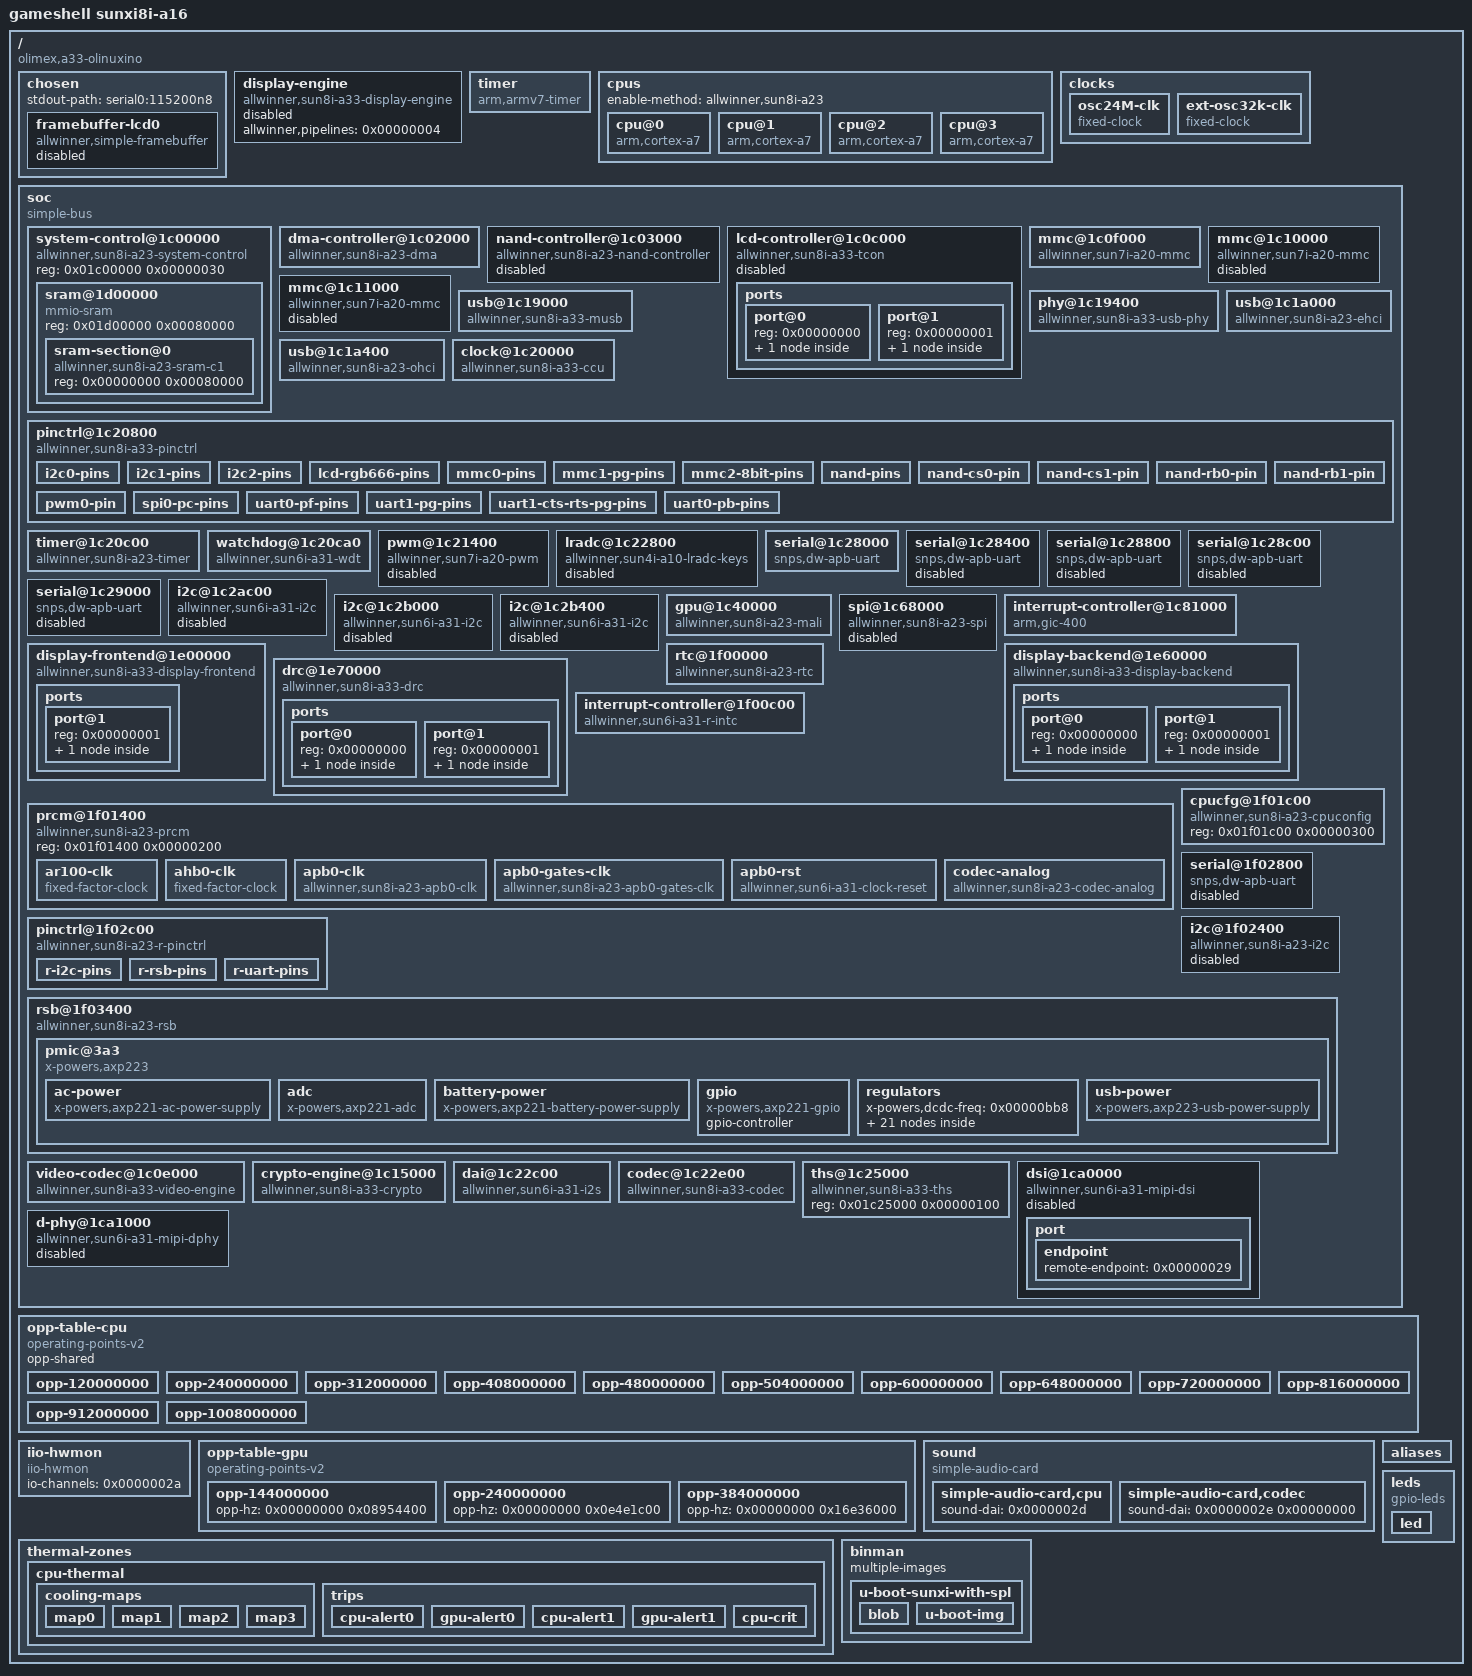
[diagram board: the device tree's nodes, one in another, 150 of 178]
/ {
        interrupt-parent = <0x00000001>;
        #address-cells = <0x00000001>;
        #size-cells = <0x00000001>;
        model = "gameshell sunxi8i-a16";
        compatible = "olimex,a33-olinuxino", "allwinner,sun8i-a33";
        chosen {
                #address-cells = <0x00000001>;
                #size-cells = <0x00000001>;
                ranges;
                stdout-path = "serial0:115200n8";
                framebuffer-lcd0 {
                        compatible = "allwinner,simple-framebuffer", "simple-framebuffer";
                        allwinner,pipeline = "de_be0-lcd0";
                        clocks = <0x00000002 0x00000026 0x00000002 0x00000028 0x00000002 0x00000057 0x00000002 0x00000055 0x00000002 0x00000054 0x00000002 0x00000062>;
                        status = "disabled";
                        vcc-lcd-supply = <0x00000003>;
                        phandle = <0x00000038>;
                };
        };
        display-engine {
                allwinner,pipelines = <0x00000004>;
                status = "disabled";
                compatible = "allwinner,sun8i-a33-display-engine";
                phandle = <0x00000039>;
        };
        timer {
                compatible = "arm,armv7-timer";
                interrupts = <0x00000001 0x0000000d 0x00000f08 0x00000001 0x0000000e 0x00000f08 0x00000001 0x0000000b 0x00000f08 0x00000001 0x0000000a 0x00000f08>;
                clock-frequency = <0x016e3600>;
                arm,cpu-registers-not-fw-configured;
        };
        cpus {
                enable-method = "allwinner,sun8i-a23";
                #address-cells = <0x00000001>;
                #size-cells = <0x00000000>;
                cpu@0 {
                        compatible = "arm,cortex-a7";
                        device_type = "cpu";
                        reg = <0x00000000>;
                        clocks = <0x00000002 0x00000012>;
                        clock-names = "cpu";
                        operating-points-v2 = <0x00000005>;
                        #cooling-cells = <0x00000002>;
                        phandle = <0x00000030>;
                };
                cpu@1 {
                        compatible = "arm,cortex-a7";
                        device_type = "cpu";
                        reg = <0x00000001>;
                        clocks = <0x00000002 0x00000012>;
                        clock-names = "cpu";
                        operating-points-v2 = <0x00000005>;
                        #cooling-cells = <0x00000002>;
                        phandle = <0x00000031>;
                };
                cpu@2 {
                        compatible = "arm,cortex-a7";
                        device_type = "cpu";
                        reg = <0x00000002>;
                        clocks = <0x00000002 0x00000012>;
                        clock-names = "cpu";
                        operating-points-v2 = <0x00000005>;
                        #cooling-cells = <0x00000002>;
                        phandle = <0x00000032>;
                };
                cpu@3 {
                        compatible = "arm,cortex-a7";
                        device_type = "cpu";
                        reg = <0x00000003>;
                        clocks = <0x00000002 0x00000012>;
                        clock-names = "cpu";
                        operating-points-v2 = <0x00000005>;
                        #cooling-cells = <0x00000002>;
                        phandle = <0x00000033>;
                };
        };
        clocks {
                #address-cells = <0x00000001>;
                #size-cells = <0x00000001>;
                ranges;
                osc24M-clk {
                        #clock-cells = <0x00000000>;
                        compatible = "fixed-clock";
                        clock-frequency = <0x016e3600>;
                        clock-accuracy = <0x0000c350>;
                        clock-output-names = "osc24M";
                        phandle = <0x00000012>;
                };
                ext-osc32k-clk {
                        #clock-cells = <0x00000000>;
                        compatible = "fixed-clock";
                        clock-frequency = <0x00008000>;
                        clock-accuracy = <0x0000c350>;
                        clock-output-names = "ext-osc32k";
                        phandle = <0x0000001e>;
                };
        };
        soc {
                compatible = "simple-bus";
                #address-cells = <0x00000001>;
                #size-cells = <0x00000001>;
                ranges;
                system-control@1c00000 {
                        compatible = "allwinner,sun8i-a23-system-control";
                        reg = <0x01c00000 0x00000030>;
                        #address-cells = <0x00000001>;
                        #size-cells = <0x00000001>;
                        ranges;
                        sram@1d00000 {
                                compatible = "mmio-sram";
                                reg = <0x01d00000 0x00080000>;
                                #address-cells = <0x00000001>;
                                #size-cells = <0x00000001>;
                                ranges = <0x00000000 0x01d00000 0x00080000>;
                                phandle = <0x0000003a>;
                                sram-section@0 {
                                        compatible = "allwinner,sun8i-a23-sram-c1", "allwinner,sun4i-a10-sram-c1";
                                        reg = <0x00000000 0x00080000>;
                                        phandle = <0x00000027>;
                                };
                        };
                };
                dma-controller@1c02000 {
                        compatible = "allwinner,sun8i-a23-dma";
                        reg = <0x01c02000 0x00001000>;
                        interrupts = <0x00000000 0x00000032 0x00000004>;
                        clocks = <0x00000002 0x00000019>;
                        resets = <0x00000002 0x00000006>;
                        #dma-cells = <0x00000001>;
                        phandle = <0x00000006>;
                };
                nand-controller@1c03000 {
                        compatible = "allwinner,sun8i-a23-nand-controller";
                        reg = <0x01c03000 0x00001000>;
                        interrupts = <0x00000000 0x00000046 0x00000004>;
                        clocks = <0x00000002 0x0000001d 0x00000002 0x0000003b>;
                        clock-names = "ahb", "mod";
                        resets = <0x00000002 0x0000000a>;
                        reset-names = "ahb";
                        dmas = <0x00000006 0x00000005>;
                        dma-names = "rxtx";
                        pinctrl-names = "default";
                        pinctrl-0 = <0x00000007 0x00000008 0x00000009>;
                        status = "disabled";
                        #address-cells = <0x00000001>;
                        #size-cells = <0x00000000>;
                        phandle = <0x0000003b>;
                };
                lcd-controller@1c0c000 {
                        reg = <0x01c0c000 0x00001000>;
                        interrupts = <0x00000000 0x00000056 0x00000004>;
                        dmas = <0x00000006 0x0000000c>;
                        clocks = <0x00000002 0x00000026 0x00000002 0x00000057 0x00000002 0x0000000d>;
                        clock-names = "ahb", "tcon-ch0", "lvds-alt";
                        clock-output-names = "tcon-data-clock";
                        #clock-cells = <0x00000000>;
                        resets = <0x00000002 0x00000013 0x00000002 0x0000001c>;
                        reset-names = "lcd", "lvds";
                        status = "disabled";
                        compatible = "allwinner,sun8i-a33-tcon";
                        phandle = <0x0000003c>;
                        ports {
                                #address-cells = <0x00000001>;
                                #size-cells = <0x00000000>;
                                port@0 {
                                        reg = <0x00000000>;
                                        phandle = <0x0000003d>;
                                        endpoint {
                                                remote-endpoint = <0x0000000a>;
                                                phandle = <0x0000001d>;
                                        };
                                };
                                port@1 {
                                        reg = <0x00000001>;
                                        #address-cells = <0x00000001>;
                                        #size-cells = <0x00000000>;
                                        phandle = <0x0000003e>;
                                        endpoint@1 {
                                                reg = <0x00000001>;
                                                remote-endpoint = <0x0000000b>;
                                                phandle = <0x00000029>;
                                        };
                                };
                        };
                };
                mmc@1c0f000 {
                        compatible = "allwinner,sun7i-a20-mmc";
                        reg = <0x01c0f000 0x00001000>;
                        clocks = <0x00000002 0x0000001a 0x00000002 0x0000003c 0x00000002 0x0000003e 0x00000002 0x0000003d>;
                        clock-names = "ahb", "mmc", "output", "sample";
                        resets = <0x00000002 0x00000007>;
                        reset-names = "ahb";
                        interrupts = <0x00000000 0x0000003c 0x00000004>;
                        pinctrl-names = "default";
                        pinctrl-0 = <0x0000000c>;
                        status = "okay";
                        #address-cells = <0x00000001>;
                        #size-cells = <0x00000000>;
                        vmmc-supply = <0x0000000d>;
                        bus-width = <0x00000004>;
                        cd-gpios = <0x0000000e 0x00000001 0x00000004 0x00000001>;
                        phandle = <0x0000003f>;
                };
                mmc@1c10000 {
                        compatible = "allwinner,sun7i-a20-mmc";
                        reg = <0x01c10000 0x00001000>;
                        clocks = <0x00000002 0x0000001b 0x00000002 0x0000003f 0x00000002 0x00000041 0x00000002 0x00000040>;
                        clock-names = "ahb", "mmc", "output", "sample";
                        resets = <0x00000002 0x00000008>;
                        reset-names = "ahb";
                        interrupts = <0x00000000 0x0000003d 0x00000004>;
                        status = "disabled";
                        #address-cells = <0x00000001>;
                        #size-cells = <0x00000000>;
                        phandle = <0x00000040>;
                };
                mmc@1c11000 {
                        compatible = "allwinner,sun7i-a20-mmc";
                        reg = <0x01c11000 0x00001000>;
                        clocks = <0x00000002 0x0000001c 0x00000002 0x00000042 0x00000002 0x00000044 0x00000002 0x00000043>;
                        clock-names = "ahb", "mmc", "output", "sample";
                        resets = <0x00000002 0x00000009>;
                        reset-names = "ahb";
                        interrupts = <0x00000000 0x0000003e 0x00000004>;
                        status = "disabled";
                        #address-cells = <0x00000001>;
                        #size-cells = <0x00000000>;
                        phandle = <0x00000041>;
                };
                usb@1c19000 {
                        reg = <0x01c19000 0x00000400>;
                        clocks = <0x00000002 0x00000022>;
                        resets = <0x00000002 0x0000000f>;
                        interrupts = <0x00000000 0x00000047 0x00000004>;
                        interrupt-names = "mc";
                        phys = <0x0000000f 0x00000000>;
                        phy-names = "usb";
                        extcon = <0x0000000f 0x00000000>;
                        dr_mode = "otg";
                        status = "okay";
                        compatible = "allwinner,sun8i-a33-musb";
                        phandle = <0x00000042>;
                };
                phy@1c19400 {
                        clocks = <0x00000002 0x0000004a 0x00000002 0x0000004b>;
                        clock-names = "usb0_phy", "usb1_phy";
                        resets = <0x00000002 0x00000000 0x00000002 0x00000001>;
                        reset-names = "usb0_reset", "usb1_reset";
                        status = "okay";
                        #phy-cells = <0x00000001>;
                        compatible = "allwinner,sun8i-a33-usb-phy";
                        reg = <0x01c19400 0x00000014 0x01c1a800 0x00000004>;
                        reg-names = "phy_ctrl", "pmu1";
                        usb0_id_det-gpios = <0x0000000e 0x00000001 0x00000003 0x00000000>;
                        usb0_vbus_power-supply = <0x00000010>;
                        usb0_vbus-supply = <0x00000011>;
                        phandle = <0x0000000f>;
                };
                usb@1c1a000 {
                        compatible = "allwinner,sun8i-a23-ehci", "generic-ehci";
                        reg = <0x01c1a000 0x00000100>;
                        interrupts = <0x00000000 0x00000048 0x00000004>;
                        clocks = <0x00000002 0x00000023>;
                        resets = <0x00000002 0x00000010>;
                        phys = <0x0000000f 0x00000001>;
                        phy-names = "usb";
                        status = "okay";
                        phandle = <0x00000043>;
                };
                usb@1c1a400 {
                        compatible = "allwinner,sun8i-a23-ohci", "generic-ohci";
                        reg = <0x01c1a400 0x00000100>;
                        interrupts = <0x00000000 0x00000049 0x00000004>;
                        clocks = <0x00000002 0x00000024 0x00000002 0x0000004e>;
                        resets = <0x00000002 0x00000011>;
                        phys = <0x0000000f 0x00000001>;
                        phy-names = "usb";
                        status = "okay";
                        phandle = <0x00000044>;
                };
                clock@1c20000 {
                        reg = <0x01c20000 0x00000400>;
                        clocks = <0x00000012 0x00000013 0x00000000>;
                        clock-names = "hosc", "losc";
                        #clock-cells = <0x00000001>;
                        #reset-cells = <0x00000001>;
                        compatible = "allwinner,sun8i-a33-ccu";
                        phandle = <0x00000002>;
                };
                pinctrl@1c20800 {
                        reg = <0x01c20800 0x00000400>;
                        clocks = <0x00000002 0x00000030 0x00000012 0x00000013 0x00000000>;
                        clock-names = "apb", "hosc", "losc";
                        gpio-controller;
                        interrupt-controller;
                        #interrupt-cells = <0x00000003>;
                        #gpio-cells = <0x00000003>;
                        compatible = "allwinner,sun8i-a33-pinctrl";
                        interrupts = <0x00000000 0x0000000f 0x00000004 0x00000000 0x00000011 0x00000004>;
                        phandle = <0x0000000e>;
                        i2c0-pins {
                                pins = "PH2", "PH3";
                                function = "i2c0";
                                phandle = <0x00000015>;
                        };
                        i2c1-pins {
                                pins = "PH4", "PH5";
                                function = "i2c1";
                                phandle = <0x00000016>;
                        };
                        i2c2-pins {
                                pins = "PE12", "PE13";
                                function = "i2c2";
                                phandle = <0x00000017>;
                        };
                        lcd-rgb666-pins {
                                pins = "PD2", "PD3", "PD4", "PD5", "PD6", "PD7", "PD10", "PD11", "PD12", "PD13", "PD14", "PD15", "PD18", "PD19", "PD20", "PD21", "PD22", "PD23", "PD24", "PD25", "PD26", "PD27";
                                function = "lcd0";
                                phandle = <0x00000045>;
                        };
                        mmc0-pins {
                                pins = "PF0", "PF1", "PF2", "PF3", "PF4", "PF5";
                                function = "mmc0";
                                drive-strength = <0x0000001e>;
                                bias-pull-up;
                                phandle = <0x0000000c>;
                        };
                        mmc1-pg-pins {
                                pins = "PG0", "PG1", "PG2", "PG3", "PG4", "PG5";
                                function = "mmc1";
                                drive-strength = <0x0000001e>;
                                bias-pull-up;
                                phandle = <0x00000046>;
                        };
                        mmc2-8bit-pins {
                                pins = "PC5", "PC6", "PC8", "PC9", "PC10", "PC11", "PC12", "PC13", "PC14", "PC15", "PC16";
                                function = "mmc2";
                                drive-strength = <0x0000001e>;
                                bias-pull-up;
                                phandle = <0x00000047>;
                        };
                        nand-pins {
                                pins = "PC0", "PC1", "PC2", "PC5", "PC8", "PC9", "PC10", "PC11", "PC12", "PC13", "PC14", "PC15";
                                function = "nand0";
                                phandle = <0x00000007>;
                        };
                        nand-cs0-pin {
                                pins = "PC4";
                                function = "nand0";
                                bias-pull-up;
                                phandle = <0x00000008>;
                        };
                        nand-cs1-pin {
                                pins = "PC3";
                                function = "nand0";
                                bias-pull-up;
                                phandle = <0x00000048>;
                        };
                        nand-rb0-pin {
                                pins = "PC6";
                                function = "nand0";
                                bias-pull-up;
                                phandle = <0x00000009>;
                        };
                        nand-rb1-pin {
                                pins = "PC7";
                                function = "nand0";
                                bias-pull-up;
                                phandle = <0x00000049>;
                        };
                        pwm0-pin {
                                pins = "PH0";
                                function = "pwm0";
                                phandle = <0x0000004a>;
                        };
                        spi0-pc-pins {
                                pins = "PC0", "PC1", "PC2", "PC3";
                                function = "spi0";
                                phandle = <0x0000004b>;
                        };
                        uart0-pf-pins {
                                pins = "PF2", "PF4";
                                function = "uart0";
                                phandle = <0x0000004c>;
                        };
                        uart1-pg-pins {
                                pins = "PG6", "PG7";
                                function = "uart1";
                                phandle = <0x0000004d>;
                        };
                        uart1-cts-rts-pg-pins {
                                pins = "PG8", "PG9";
                                function = "uart1";
                                phandle = <0x0000004e>;
                        };
                        uart0-pb-pins {
                                pins = "PB0", "PB1";
                                function = "uart0";
                                phandle = <0x00000014>;
                        };
                };
                timer@1c20c00 {
                        compatible = "allwinner,sun8i-a23-timer";
                        reg = <0x01c20c00 0x000000a0>;
                        interrupts = <0x00000000 0x00000012 0x00000004 0x00000000 0x00000013 0x00000004>;
                        clocks = <0x00000012>;
                };
                watchdog@1c20ca0 {
                        compatible = "allwinner,sun6i-a31-wdt";
                        reg = <0x01c20ca0 0x00000020>;
                        interrupts = <0x00000000 0x00000019 0x00000004>;
                        clocks = <0x00000012>;
                        phandle = <0x0000004f>;
                };
                pwm@1c21400 {
                        compatible = "allwinner,sun7i-a20-pwm";
                        reg = <0x01c21400 0x0000000c>;
                        clocks = <0x00000012>;
                        #pwm-cells = <0x00000003>;
                        status = "disabled";
                        phandle = <0x00000050>;
                };
                lradc@1c22800 {
                        compatible = "allwinner,sun4i-a10-lradc-keys";
                        reg = <0x01c22800 0x00000100>;
                        interrupts = <0x00000000 0x0000001e 0x00000004>;
                        status = "disabled";
                        phandle = <0x00000051>;
                };
                serial@1c28000 {
                        compatible = "snps,dw-apb-uart";
                        reg = <0x01c28000 0x00000400>;
                        interrupts = <0x00000000 0x00000000 0x00000004>;
                        reg-shift = <0x00000002>;
                        reg-io-width = <0x00000004>;
                        clocks = <0x00000002 0x00000036>;
                        resets = <0x00000002 0x00000023>;
                        dmas = <0x00000006 0x00000006 0x00000006 0x00000006>;
                        dma-names = "tx", "rx";
                        status = "okay";
                        pinctrl-names = "default";
                        pinctrl-0 = <0x00000014>;
                        phandle = <0x00000052>;
                };
                serial@1c28400 {
                        compatible = "snps,dw-apb-uart";
                        reg = <0x01c28400 0x00000400>;
                        interrupts = <0x00000000 0x00000001 0x00000004>;
                        reg-shift = <0x00000002>;
                        reg-io-width = <0x00000004>;
                        clocks = <0x00000002 0x00000037>;
                        resets = <0x00000002 0x00000024>;
                        dmas = <0x00000006 0x00000007 0x00000006 0x00000007>;
                        dma-names = "tx", "rx";
                        status = "disabled";
                        phandle = <0x00000053>;
                };
                serial@1c28800 {
                        compatible = "snps,dw-apb-uart";
                        reg = <0x01c28800 0x00000400>;
                        interrupts = <0x00000000 0x00000002 0x00000004>;
                        reg-shift = <0x00000002>;
                        reg-io-width = <0x00000004>;
                        clocks = <0x00000002 0x00000038>;
                        resets = <0x00000002 0x00000025>;
                        dmas = <0x00000006 0x00000008 0x00000006 0x00000008>;
                        dma-names = "tx", "rx";
                        status = "disabled";
                        phandle = <0x00000054>;
                };
                serial@1c28c00 {
                        compatible = "snps,dw-apb-uart";
                        reg = <0x01c28c00 0x00000400>;
                        interrupts = <0x00000000 0x00000003 0x00000004>;
                        reg-shift = <0x00000002>;
                        reg-io-width = <0x00000004>;
                        clocks = <0x00000002 0x00000039>;
                        resets = <0x00000002 0x00000026>;
                        dmas = <0x00000006 0x00000009 0x00000006 0x00000009>;
                        dma-names = "tx", "rx";
                        status = "disabled";
                        phandle = <0x00000055>;
                };
                serial@1c29000 {
                        compatible = "snps,dw-apb-uart";
                        reg = <0x01c29000 0x00000400>;
                        interrupts = <0x00000000 0x00000004 0x00000004>;
                        reg-shift = <0x00000002>;
                        reg-io-width = <0x00000004>;
                        clocks = <0x00000002 0x0000003a>;
                        resets = <0x00000002 0x00000027>;
                        dmas = <0x00000006 0x0000000a 0x00000006 0x0000000a>;
                        dma-names = "tx", "rx";
                        status = "disabled";
                        phandle = <0x00000056>;
                };
                i2c@1c2ac00 {
                        compatible = "allwinner,sun6i-a31-i2c";
                        reg = <0x01c2ac00 0x00000400>;
                        interrupts = <0x00000000 0x00000006 0x00000004>;
                        clocks = <0x00000002 0x00000033>;
                        resets = <0x00000002 0x00000020>;
                        pinctrl-names = "default";
                        pinctrl-0 = <0x00000015>;
                        status = "disabled";
                        #address-cells = <0x00000001>;
                        #size-cells = <0x00000000>;
                        phandle = <0x00000057>;
                };
                i2c@1c2b000 {
                        compatible = "allwinner,sun6i-a31-i2c";
                        reg = <0x01c2b000 0x00000400>;
                        interrupts = <0x00000000 0x00000007 0x00000004>;
                        clocks = <0x00000002 0x00000034>;
                        resets = <0x00000002 0x00000021>;
                        pinctrl-names = "default";
                        pinctrl-0 = <0x00000016>;
                        status = "disabled";
                        #address-cells = <0x00000001>;
                        #size-cells = <0x00000000>;
                        phandle = <0x00000058>;
                };
                i2c@1c2b400 {
                        compatible = "allwinner,sun6i-a31-i2c";
                        reg = <0x01c2b400 0x00000400>;
                        interrupts = <0x00000000 0x00000008 0x00000004>;
                        clocks = <0x00000002 0x00000035>;
                        resets = <0x00000002 0x00000022>;
                        pinctrl-names = "default";
                        pinctrl-0 = <0x00000017>;
                        status = "disabled";
                        #address-cells = <0x00000001>;
                        #size-cells = <0x00000000>;
                        phandle = <0x00000059>;
                };
                gpu@1c40000 {
                        compatible = "allwinner,sun8i-a23-mali", "allwinner,sun7i-a20-mali", "arm,mali-400";
                        reg = <0x01c40000 0x00010000>;
                        interrupts = <0x00000000 0x00000061 0x00000004 0x00000000 0x00000062 0x00000004 0x00000000 0x00000063 0x00000004 0x00000000 0x00000064 0x00000004 0x00000000 0x00000066 0x00000004 0x00000000 0x00000067 0x00000004 0x00000000 0x00000065 0x00000004>;
                        interrupt-names = "gp", "gpmmu", "pp0", "ppmmu0", "pp1", "ppmmu1", "pmu";
                        clocks = <0x00000002 0x0000002a 0x00000002 0x00000063>;
                        clock-names = "bus", "core";
                        resets = <0x00000002 0x00000017>;
                        #cooling-cells = <0x00000002>;
                        assigned-clocks = <0x00000002 0x00000063>;
                        assigned-clock-rates = <0x16e36000>;
                        operating-points-v2 = <0x00000018>;
                        phandle = <0x00000036>;
                };
                spi@1c68000 {
                        compatible = "allwinner,sun8i-a23-spi", "allwinner,sun8i-h3-spi";
                        reg = <0x01c68000 0x00001000>;
                        interrupts = <0x00000000 0x00000041 0x00000004>;
                        clocks = <0x00000002 0x00000020 0x00000002 0x00000046>;
                        clock-names = "ahb", "mod";
                        dmas = <0x00000006 0x00000017 0x00000006 0x00000017>;
                        dma-names = "rx", "tx";
                        resets = <0x00000002 0x0000000d>;
                        status = "disabled";
                        #address-cells = <0x00000001>;
                        #size-cells = <0x00000000>;
                        phandle = <0x0000005a>;
                };
                interrupt-controller@1c81000 {
                        compatible = "arm,gic-400";
                        reg = <0x01c81000 0x00001000 0x01c82000 0x00002000 0x01c84000 0x00002000 0x01c86000 0x00002000>;
                        interrupt-controller;
                        #interrupt-cells = <0x00000003>;
                        interrupts = <0x00000001 0x00000009 0x00000f04>;
                        phandle = <0x00000001>;
                };
                display-frontend@1e00000 {
                        reg = <0x01e00000 0x00020000>;
                        interrupts = <0x00000000 0x0000005d 0x00000004>;
                        clocks = <0x00000002 0x00000029 0x00000002 0x00000056 0x00000002 0x00000053>;
                        clock-names = "ahb", "mod", "ram";
                        resets = <0x00000002 0x00000016>;
                        compatible = "allwinner,sun8i-a33-display-frontend";
                        phandle = <0x00000004>;
                        ports {
                                #address-cells = <0x00000001>;
                                #size-cells = <0x00000000>;
                                port@1 {
                                        reg = <0x00000001>;
                                        phandle = <0x0000005b>;
                                        endpoint {
                                                remote-endpoint = <0x00000019>;
                                                phandle = <0x0000001a>;
                                        };
                                };
                        };
                };
                display-backend@1e60000 {
                        reg = <0x01e60000 0x00010000 0x01e80000 0x00001000>;
                        interrupts = <0x00000000 0x0000005f 0x00000004>;
                        clocks = <0x00000002 0x00000028 0x00000002 0x00000055 0x00000002 0x00000054 0x00000002 0x0000002e>;
                        clock-names = "ahb", "mod", "ram", "sat";
                        resets = <0x00000002 0x00000015 0x00000002 0x0000001b>;
                        compatible = "allwinner,sun8i-a33-display-backend";
                        reg-names = "be", "sat";
                        reset-names = "be", "sat";
                        phandle = <0x0000005c>;
                        ports {
                                #address-cells = <0x00000001>;
                                #size-cells = <0x00000000>;
                                port@0 {
                                        reg = <0x00000000>;
                                        phandle = <0x0000005d>;
                                        endpoint {
                                                remote-endpoint = <0x0000001a>;
                                                phandle = <0x00000019>;
                                        };
                                };
                                port@1 {
                                        reg = <0x00000001>;
                                        phandle = <0x0000005e>;
                                        endpoint {
                                                remote-endpoint = <0x0000001b>;
                                                phandle = <0x0000001c>;
                                        };
                                };
                        };
                };
                drc@1e70000 {
                        reg = <0x01e70000 0x00010000>;
                        interrupts = <0x00000000 0x0000005b 0x00000004>;
                        clocks = <0x00000002 0x0000002d 0x00000002 0x00000062 0x00000002 0x00000052>;
                        clock-names = "ahb", "mod", "ram";
                        resets = <0x00000002 0x0000001a>;
                        compatible = "allwinner,sun8i-a33-drc";
                        phandle = <0x0000005f>;
                        ports {
                                #address-cells = <0x00000001>;
                                #size-cells = <0x00000000>;
                                port@0 {
                                        reg = <0x00000000>;
                                        phandle = <0x00000060>;
                                        endpoint {
                                                remote-endpoint = <0x0000001c>;
                                                phandle = <0x0000001b>;
                                        };
                                };
                                port@1 {
                                        reg = <0x00000001>;
                                        phandle = <0x00000061>;
                                        endpoint {
                                                remote-endpoint = <0x0000001d>;
                                                phandle = <0x0000000a>;
                                        };
                                };
                        };
                };
                rtc@1f00000 {
                        compatible = "allwinner,sun8i-a23-rtc";
                        reg = <0x01f00000 0x00000400>;
                        interrupts = <0x00000000 0x00000028 0x00000004 0x00000000 0x00000029 0x00000004>;
                        clock-output-names = "osc32k", "osc32k-out";
                        clocks = <0x0000001e>;
                        #clock-cells = <0x00000001>;
                        phandle = <0x00000013>;
                };
                interrupt-controller@1f00c00 {
                        compatible = "allwinner,sun6i-a31-r-intc";
                        interrupt-controller;
                        #interrupt-cells = <0x00000002>;
                        reg = <0x01f00c00 0x00000400>;
                        interrupts = <0x00000000 0x00000020 0x00000004>;
                        phandle = <0x00000026>;
                };
                prcm@1f01400 {
                        compatible = "allwinner,sun8i-a23-prcm";
                        reg = <0x01f01400 0x00000200>;
                        ar100-clk {
                                compatible = "fixed-factor-clock";
                                #clock-cells = <0x00000000>;
                                clock-div = <0x00000001>;
                                clock-mult = <0x00000001>;
                                clocks = <0x00000012>;
                                clock-output-names = "ar100";
                                phandle = <0x0000001f>;
                        };
                        ahb0-clk {
                                compatible = "fixed-factor-clock";
                                #clock-cells = <0x00000000>;
                                clock-div = <0x00000001>;
                                clock-mult = <0x00000001>;
                                clocks = <0x0000001f>;
                                clock-output-names = "ahb0";
                                phandle = <0x00000020>;
                        };
                        apb0-clk {
                                compatible = "allwinner,sun8i-a23-apb0-clk";
                                #clock-cells = <0x00000000>;
                                clocks = <0x00000020>;
                                clock-output-names = "apb0";
                                phandle = <0x00000021>;
                        };
                        apb0-gates-clk {
                                compatible = "allwinner,sun8i-a23-apb0-gates-clk";
                                #clock-cells = <0x00000001>;
                                clocks = <0x00000021>;
                                clock-output-names = "apb0_pio", "apb0_timer", "apb0_rsb", "apb0_uart", "apb0_i2c";
                                phandle = <0x00000022>;
                        };
                        apb0-rst {
                                compatible = "allwinner,sun6i-a31-clock-reset";
                                #reset-cells = <0x00000001>;
                                phandle = <0x00000023>;
                        };
                        codec-analog {
                                compatible = "allwinner,sun8i-a23-codec-analog";
                                phandle = <0x0000002c>;
                        };
                };
                cpucfg@1f01c00 {
                        compatible = "allwinner,sun8i-a23-cpuconfig";
                        reg = <0x01f01c00 0x00000300>;
                };
                serial@1f02800 {
                        compatible = "snps,dw-apb-uart";
                        reg = <0x01f02800 0x00000400>;
                        interrupts = <0x00000000 0x00000026 0x00000004>;
                        reg-shift = <0x00000002>;
                        reg-io-width = <0x00000004>;
                        clocks = <0x00000022 0x00000004>;
                        resets = <0x00000023 0x00000004>;
                        status = "disabled";
                        phandle = <0x00000062>;
                };
                i2c@1f02400 {
                        compatible = "allwinner,sun8i-a23-i2c", "allwinner,sun6i-a31-i2c";
                        reg = <0x01f02400 0x00000400>;
                        interrupts = <0x00000000 0x0000002c 0x00000004>;
                        pinctrl-names = "default";
                        pinctrl-0 = <0x00000024>;
                        clocks = <0x00000022 0x00000006>;
                        resets = <0x00000023 0x00000006>;
                        status = "disabled";
                        #address-cells = <0x00000001>;
                        #size-cells = <0x00000000>;
                        phandle = <0x00000063>;
                };
                pinctrl@1f02c00 {
                        compatible = "allwinner,sun8i-a23-r-pinctrl";
                        reg = <0x01f02c00 0x00000400>;
                        interrupts = <0x00000000 0x0000002d 0x00000004>;
                        clocks = <0x00000022 0x00000000 0x00000012 0x00000013 0x00000000>;
                        clock-names = "apb", "hosc", "losc";
                        gpio-controller;
                        interrupt-controller;
                        #interrupt-cells = <0x00000003>;
                        #gpio-cells = <0x00000003>;
                        phandle = <0x00000064>;
                        r-i2c-pins {
                                pins = "PL0", "PL1";
                                function = "s_i2c";
                                bias-pull-up;
                                phandle = <0x00000024>;
                        };
                        r-rsb-pins {
                                pins = "PL0", "PL1";
                                function = "s_rsb";
                                drive-strength = <0x00000014>;
                                bias-pull-up;
                                phandle = <0x00000025>;
                        };
                        r-uart-pins {
                                pins = "PL2", "PL3";
                                function = "s_uart";
                                phandle = <0x00000065>;
                        };
                };
                rsb@1f03400 {
                        compatible = "allwinner,sun8i-a23-rsb";
                        reg = <0x01f03400 0x00000400>;
                        interrupts = <0x00000000 0x00000027 0x00000004>;
                        clocks = <0x00000022 0x00000003>;
                        clock-frequency = <0x002dc6c0>;
                        resets = <0x00000023 0x00000003>;
                        pinctrl-names = "default";
                        pinctrl-0 = <0x00000025>;
                        status = "okay";
                        #address-cells = <0x00000001>;
                        #size-cells = <0x00000000>;
                        phandle = <0x00000066>;
                        pmic@3a3 {
                                compatible = "x-powers,axp223";
                                reg = <0x000003a3>;
                                interrupt-parent = <0x00000026>;
                                interrupts = <0x00000000 0x00000008>;
                                eldoin-supply = <0x0000000d>;
                                x-powers,drive-vbus-en;
                                interrupt-controller;
                                #interrupt-cells = <0x00000001>;
                                phandle = <0x00000067>;
                                ac-power {
                                        compatible = "x-powers,axp221-ac-power-supply";
                                        status = "okay";
                                        phandle = <0x00000068>;
                                };
                                adc {
                                        compatible = "x-powers,axp221-adc";
                                        #io-channel-cells = <0x00000001>;
                                        phandle = <0x00000069>;
                                };
                                battery-power {
                                        compatible = "x-powers,axp221-battery-power-supply";
                                        status = "okay";
                                        phandle = <0x0000006a>;
                                };
                                gpio {
                                        compatible = "x-powers,axp221-gpio";
                                        gpio-controller;
                                        #gpio-cells = <0x00000002>;
                                        phandle = <0x0000006b>;
                                };
                                regulators {
                                        x-powers,dcdc-freq = <0x00000bb8>;
                                        dcdc1 {
                                                regulator-name = "vcc-3v3";
                                                regulator-always-on;
                                                regulator-min-microvolt = <0x00325aa0>;
                                                regulator-max-microvolt = <0x00325aa0>;
                                                phandle = <0x0000000d>;
                                        };
                                        dcdc2 {
                                                regulator-name = "vdd-sys";
                                                regulator-always-on;
                                                regulator-min-microvolt = <0x000dbba0>;
                                                regulator-max-microvolt = <0x00155cc0>;
                                                phandle = <0x0000006c>;
                                        };
                                        dcdc3 {
                                                regulator-name = "vdd-cpu";
                                                regulator-always-on;
                                                regulator-min-microvolt = <0x000dbba0>;
                                                regulator-max-microvolt = <0x00155cc0>;
                                                phandle = <0x0000006d>;
                                        };
                                        dcdc4 {
                                                regulator-name = "dcdc4";
                                                phandle = <0x0000006e>;
                                        };
                                        dcdc5 {
                                                regulator-name = "vcc-dram";
                                                regulator-always-on;
                                                regulator-min-microvolt = <0x0016e360>;
                                                regulator-max-microvolt = <0x0016e360>;
                                                phandle = <0x0000006f>;
                                        };
                                        dc1sw {
                                                regulator-name = "vcc-lcd";
                                                phandle = <0x00000003>;
                                        };
                                        dc5ldo {
                                                regulator-name = "vdd-cpus";
                                                regulator-always-on;
                                                regulator-min-microvolt = <0x000dbba0>;
                                                regulator-max-microvolt = <0x00155cc0>;
                                                phandle = <0x00000070>;
                                        };
                                        aldo1 {
                                                regulator-name = "vcc-io";
                                                regulator-always-on;
                                                regulator-min-microvolt = <0x00325aa0>;
                                                regulator-max-microvolt = <0x00325aa0>;
                                                phandle = <0x00000071>;
                                        };
                                        aldo2 {
                                                regulator-name = "vdd-dll";
                                                regulator-always-on;
                                                regulator-min-microvolt = <0x0023dbb0>;
                                                regulator-max-microvolt = <0x00286f90>;
                                                phandle = <0x00000072>;
                                        };
                                        aldo3 {
                                                regulator-name = "vcc-avcc";
                                                regulator-always-on;
                                                regulator-min-microvolt = <0x00325aa0>;
                                                regulator-max-microvolt = <0x00325aa0>;
                                                phandle = <0x00000073>;
                                        };
                                        dldo1 {
                                                regulator-name = "dldo1";
                                                phandle = <0x00000074>;
                                        };
                                        dldo2 {
                                                regulator-name = "dldo2";
                                                phandle = <0x00000075>;
                                        };
                                        dldo3 {
                                                regulator-name = "dldo3";
                                                phandle = <0x00000076>;
                                        };
                                        dldo4 {
                                                regulator-name = "dldo4";
                                                phandle = <0x00000077>;
                                        };
                                        eldo1 {
                                                regulator-name = "eldo1";
                                                phandle = <0x00000078>;
                                        };
                                        eldo2 {
                                                regulator-name = "eldo2";
                                                phandle = <0x00000079>;
                                        };
                                        eldo3 {
                                                regulator-name = "eldo3";
                                                phandle = <0x0000007a>;
                                        };
                                        ldo_io0 {
                                                regulator-name = "ldo_io0";
                                                status = "disabled";
                                                phandle = <0x0000007b>;
                                        };
                                        ldo_io1 {
                                                regulator-name = "ldo_io1";
                                                status = "disabled";
                                                phandle = <0x0000007c>;
                                        };
                                        rtc_ldo {
                                                regulator-always-on;
                                                regulator-min-microvolt = <0x002dc6c0>;
                                                regulator-max-microvolt = <0x002dc6c0>;
                                                regulator-name = "vcc-rtc";
                                                phandle = <0x0000007d>;
                                        };
                                        drivevbus {
                                                regulator-name = "usb0-vbus";
                                                status = "okay";
                                                phandle = <0x00000011>;
                                        };
                                };
                                usb-power {
                                        compatible = "x-powers,axp223-usb-power-supply";
                                        status = "okay";
                                        phandle = <0x00000010>;
                                };
                        };
                };
                video-codec@1c0e000 {
                        compatible = "allwinner,sun8i-a33-video-engine";
                        reg = <0x01c0e000 0x00001000>;
                        clocks = <0x00000002 0x00000025 0x00000002 0x0000005b 0x00000002 0x00000050>;
                        clock-names = "ahb", "mod", "ram";
                        resets = <0x00000002 0x00000012>;
                        interrupts = <0x00000000 0x0000003a 0x00000004>;
                        allwinner,sram = <0x00000027 0x00000001>;
                };
                crypto-engine@1c15000 {
                        compatible = "allwinner,sun8i-a33-crypto";
                        reg = <0x01c15000 0x00001000>;
                        interrupts = <0x00000000 0x00000050 0x00000004>;
                        clocks = <0x00000002 0x00000018 0x00000002 0x00000045>;
                        clock-names = "ahb", "mod";
                        resets = <0x00000002 0x00000005>;
                        reset-names = "ahb";
                        phandle = <0x0000007e>;
                };
                dai@1c22c00 {
                        #sound-dai-cells = <0x00000000>;
                        compatible = "allwinner,sun6i-a31-i2s";
                        reg = <0x01c22c00 0x00000200>;
                        interrupts = <0x00000000 0x0000001d 0x00000004>;
                        clocks = <0x00000002 0x0000002f 0x00000002 0x0000005c>;
                        clock-names = "apb", "mod";
                        resets = <0x00000002 0x0000001d>;
                        dmas = <0x00000006 0x0000000f 0x00000006 0x0000000f>;
                        dma-names = "rx", "tx";
                        status = "okay";
                        phandle = <0x0000002d>;
                };
                codec@1c22e00 {
                        #sound-dai-cells = <0x00000001>;
                        compatible = "allwinner,sun8i-a33-codec";
                        reg = <0x01c22e00 0x00000400>;
                        interrupts = <0x00000000 0x0000001d 0x00000004>;
                        clocks = <0x00000002 0x0000002f 0x00000002 0x0000005c>;
                        clock-names = "bus", "mod";
                        status = "okay";
                        phandle = <0x0000002e>;
                };
                ths@1c25000 {
                        compatible = "allwinner,sun8i-a33-ths";
                        reg = <0x01c25000 0x00000100>;
                        #thermal-sensor-cells = <0x00000000>;
                        #io-channel-cells = <0x00000000>;
                        phandle = <0x0000002a>;
                };
                dsi@1ca0000 {
                        compatible = "allwinner,sun6i-a31-mipi-dsi";
                        reg = <0x01ca0000 0x00001000>;
                        interrupts = <0x00000000 0x00000059 0x00000004>;
                        clocks = <0x00000002 0x00000017 0x00000002 0x00000060>;
                        clock-names = "bus", "mod";
                        resets = <0x00000002 0x00000004>;
                        phys = <0x00000028>;
                        phy-names = "dphy";
                        status = "disabled";
                        #address-cells = <0x00000001>;
                        #size-cells = <0x00000000>;
                        phandle = <0x0000007f>;
                        port {
                                endpoint {
                                        remote-endpoint = <0x00000029>;
                                        phandle = <0x0000000b>;
                                };
                        };
                };
                d-phy@1ca1000 {
                        compatible = "allwinner,sun6i-a31-mipi-dphy";
                        reg = <0x01ca1000 0x00001000>;
                        interrupts = <0x00000000 0x00000059 0x00000004>;
                        clocks = <0x00000002 0x00000017 0x00000002 0x00000061>;
                        clock-names = "bus", "mod";
                        resets = <0x00000002 0x00000004>;
                        status = "disabled";
                        #phy-cells = <0x00000000>;
                        phandle = <0x00000028>;
                };
        };
        opp-table-cpu {
                compatible = "operating-points-v2";
                opp-shared;
                phandle = <0x00000005>;
                opp-120000000 {
                        opp-hz = <0x00000000 0x07270e00>;
                        opp-microvolt = <0x000fde80>;
                        clock-latency-ns = <0x0003b9b0>;
                };
                opp-240000000 {
                        opp-hz = <0x00000000 0x0e4e1c00>;
                        opp-microvolt = <0x000fde80>;
                        clock-latency-ns = <0x0003b9b0>;
                };
                opp-312000000 {
                        opp-hz = <0x00000000 0x1298be00>;
                        opp-microvolt = <0x000fde80>;
                        clock-latency-ns = <0x0003b9b0>;
                };
                opp-408000000 {
                        opp-hz = <0x00000000 0x18519600>;
                        opp-microvolt = <0x000fde80>;
                        clock-latency-ns = <0x0003b9b0>;
                };
                opp-480000000 {
                        opp-hz = <0x00000000 0x1c9c3800>;
                        opp-microvolt = <0x000fde80>;
                        clock-latency-ns = <0x0003b9b0>;
                };
                opp-504000000 {
                        opp-hz = <0x00000000 0x1e0a6e00>;
                        opp-microvolt = <0x000fde80>;
                        clock-latency-ns = <0x0003b9b0>;
                };
                opp-600000000 {
                        opp-hz = <0x00000000 0x23c34600>;
                        opp-microvolt = <0x000fde80>;
                        clock-latency-ns = <0x0003b9b0>;
                };
                opp-648000000 {
                        opp-hz = <0x00000000 0x269fb200>;
                        opp-microvolt = <0x000fde80>;
                        clock-latency-ns = <0x0003b9b0>;
                };
                opp-720000000 {
                        opp-hz = <0x00000000 0x2aea5400>;
                        opp-microvolt = <0x0010c8e0>;
                        clock-latency-ns = <0x0003b9b0>;
                };
                opp-816000000 {
                        opp-hz = <0x00000000 0x30a32c00>;
                        opp-microvolt = <0x0010c8e0>;
                        clock-latency-ns = <0x0003b9b0>;
                };
                opp-912000000 {
                        opp-hz = <0x00000000 0x365c0400>;
                        opp-microvolt = <0x00124f80>;
                        clock-latency-ns = <0x0003b9b0>;
                };
                opp-1008000000 {
                        opp-hz = <0x00000000 0x3c14dc00>;
                        opp-microvolt = <0x00124f80>;
                        clock-latency-ns = <0x0003b9b0>;
                };
        };
        iio-hwmon {
                compatible = "iio-hwmon";
                io-channels = <0x0000002a>;
        };
        opp-table-gpu {
                compatible = "operating-points-v2";
                phandle = <0x00000018>;
                opp-144000000 {
                        opp-hz = <0x00000000 0x08954400>;
                };
                opp-240000000 {
                        opp-hz = <0x00000000 0x0e4e1c00>;
                };
                opp-384000000 {
                        opp-hz = <0x00000000 0x16e36000>;
                };
        };
        sound {
                compatible = "simple-audio-card";
                simple-audio-card,name = "sun8i-a33-audio";
                simple-audio-card,format = "i2s";
                simple-audio-card,frame-master = <0x0000002b>;
                simple-audio-card,bitclock-master = <0x0000002b>;
                simple-audio-card,mclk-fs = <0x00000080>;
                simple-audio-card,aux-devs = <0x0000002c>;
                simple-audio-card,routing = "Left DAC", "DACL", "Right DAC", "DACR", "HP", "HPCOM", "Headphone Jack", "HP", "MIC1", "Microphone Jack", "Microphone Jack", "MBIAS";
                status = "okay";
                simple-audio-card,widgets = "Microphone", "Microphone Jack", "Headphone", "Headphone Jack";
                phandle = <0x00000080>;
                simple-audio-card,cpu {
                        sound-dai = <0x0000002d>;
                };
                simple-audio-card,codec {
                        sound-dai = <0x0000002e 0x00000000>;
                        phandle = <0x0000002b>;
                };
        };
        thermal-zones {
                cpu-thermal {
                        polling-delay-passive = <0x000000fa>;
                        polling-delay = <0x000003e8>;
                        thermal-sensors = <0x0000002a>;
                        cooling-maps {
                                map0 {
                                        trip = <0x0000002f>;
                                        cooling-device = <0x00000030 0xffffffff 0xffffffff 0x00000031 0xffffffff 0xffffffff 0x00000032 0xffffffff 0xffffffff 0x00000033 0xffffffff 0xffffffff>;
                                };
                                map1 {
                                        trip = <0x00000034>;
                                        cooling-device = <0x00000030 0xffffffff 0xffffffff 0x00000031 0xffffffff 0xffffffff 0x00000032 0xffffffff 0xffffffff 0x00000033 0xffffffff 0xffffffff>;
                                };
                                map2 {
                                        trip = <0x00000035>;
                                        cooling-device = <0x00000036 0x00000001 0xffffffff>;
                                };
                                map3 {
                                        trip = <0x00000037>;
                                        cooling-device = <0x00000036 0x00000002 0xffffffff>;
                                };
                        };
                        trips {
                                cpu-alert0 {
                                        temperature = <0x000124f8>;
                                        hysteresis = <0x000007d0>;
                                        type = "passive";
                                        phandle = <0x0000002f>;
                                };
                                gpu-alert0 {
                                        temperature = <0x00014c08>;
                                        hysteresis = <0x000007d0>;
                                        type = "passive";
                                        phandle = <0x00000035>;
                                };
                                cpu-alert1 {
                                        temperature = <0x00015f90>;
                                        hysteresis = <0x000007d0>;
                                        type = "hot";
                                        phandle = <0x00000034>;
                                };
                                gpu-alert1 {
                                        temperature = <0x00017318>;
                                        hysteresis = <0x000007d0>;
                                        type = "hot";
                                        phandle = <0x00000037>;
                                };
                                cpu-crit {
                                        temperature = <0x0001adb0>;
                                        hysteresis = <0x000007d0>;
                                        type = "critical";
                                        phandle = <0x00000081>;
                                };
                        };
                };
        };
        aliases {
                serial0 = "/soc/serial@1c28000";
                mmc0 = "/soc/mmc@1c0f000";
        };
        leds {
                compatible = "gpio-leds";
                led {
                        label = "a33-olinuxino:green:usr";
                        gpios = <0x0000000e 0x00000001 0x00000007 0x00000000>;
                };
        };
        binman {
                multiple-images;
                phandle = <0x00000082>;
                u-boot-sunxi-with-spl {
                        filename = "u-boot-sunxi-with-spl.bin";
                        pad-byte = <0x000000ff>;
                        blob {
                                min-size = <0x00008000>;
                                filename = "spl/sunxi-spl.bin";
                        };
                        u-boot-img {
                        };
                };
        };
        __symbols__ {
                simplefb_lcd = "/chosen/framebuffer-lcd0";
                de = "/display-engine";
                cpu0 = "/cpus/cpu@0";
                cpu1 = "/cpus/cpu@1";
                cpu2 = "/cpus/cpu@2";
                cpu3 = "/cpus/cpu@3";
                osc24M = "/clocks/osc24M-clk";
                ext_osc32k = "/clocks/ext-osc32k-clk";
                sram_c = "/soc/system-control@1c00000/sram@1d00000";
                ve_sram = "/soc/system-control@1c00000/sram@1d00000/sram-section@0";
                dma = "/soc/dma-controller@1c02000";
                nfc = "/soc/nand-controller@1c03000";
                tcon0 = "/soc/lcd-controller@1c0c000";
                tcon0_in = "/soc/lcd-controller@1c0c000/ports/port@0";
                tcon0_in_drc0 = "/soc/lcd-controller@1c0c000/ports/port@0/endpoint";
                tcon0_out = "/soc/lcd-controller@1c0c000/ports/port@1";
                tcon0_out_dsi = "/soc/lcd-controller@1c0c000/ports/port@1/endpoint@1";
                mmc0 = "/soc/mmc@1c0f000";
                mmc1 = "/soc/mmc@1c10000";
                mmc2 = "/soc/mmc@1c11000";
                usb_otg = "/soc/usb@1c19000";
                usbphy = "/soc/phy@1c19400";
                ehci0 = "/soc/usb@1c1a000";
                ohci0 = "/soc/usb@1c1a400";
                ccu = "/soc/clock@1c20000";
                pio = "/soc/pinctrl@1c20800";
                i2c0_pins = "/soc/pinctrl@1c20800/i2c0-pins";
                i2c1_pins = "/soc/pinctrl@1c20800/i2c1-pins";
                i2c2_pins = "/soc/pinctrl@1c20800/i2c2-pins";
                lcd_rgb666_pins = "/soc/pinctrl@1c20800/lcd-rgb666-pins";
                mmc0_pins = "/soc/pinctrl@1c20800/mmc0-pins";
                mmc1_pg_pins = "/soc/pinctrl@1c20800/mmc1-pg-pins";
                mmc2_8bit_pins = "/soc/pinctrl@1c20800/mmc2-8bit-pins";
                nand_pins = "/soc/pinctrl@1c20800/nand-pins";
                nand_cs0_pin = "/soc/pinctrl@1c20800/nand-cs0-pin";
                nand_cs1_pin = "/soc/pinctrl@1c20800/nand-cs1-pin";
                nand_rb0_pin = "/soc/pinctrl@1c20800/nand-rb0-pin";
                nand_rb1_pin = "/soc/pinctrl@1c20800/nand-rb1-pin";
                pwm0_pin = "/soc/pinctrl@1c20800/pwm0-pin";
                spi0_pc_pins = "/soc/pinctrl@1c20800/spi0-pc-pins";
                uart0_pf_pins = "/soc/pinctrl@1c20800/uart0-pf-pins";
                uart1_pg_pins = "/soc/pinctrl@1c20800/uart1-pg-pins";
                uart1_cts_rts_pg_pins = "/soc/pinctrl@1c20800/uart1-cts-rts-pg-pins";
                uart0_pb_pins = "/soc/pinctrl@1c20800/uart0-pb-pins";
                wdt0 = "/soc/watchdog@1c20ca0";
                pwm = "/soc/pwm@1c21400";
                lradc = "/soc/lradc@1c22800";
                uart0 = "/soc/serial@1c28000";
                uart1 = "/soc/serial@1c28400";
                uart2 = "/soc/serial@1c28800";
                uart3 = "/soc/serial@1c28c00";
                uart4 = "/soc/serial@1c29000";
                i2c0 = "/soc/i2c@1c2ac00";
                i2c1 = "/soc/i2c@1c2b000";
                i2c2 = "/soc/i2c@1c2b400";
                mali = "/soc/gpu@1c40000";
                spi0 = "/soc/spi@1c68000";
                gic = "/soc/interrupt-controller@1c81000";
                fe0 = "/soc/display-frontend@1e00000";
                fe0_out = "/soc/display-frontend@1e00000/ports/port@1";
                fe0_out_be0 = "/soc/display-frontend@1e00000/ports/port@1/endpoint";
                be0 = "/soc/display-backend@1e60000";
                be0_in = "/soc/display-backend@1e60000/ports/port@0";
                be0_in_fe0 = "/soc/display-backend@1e60000/ports/port@0/endpoint";
                be0_out = "/soc/display-backend@1e60000/ports/port@1";
                be0_out_drc0 = "/soc/display-backend@1e60000/ports/port@1/endpoint";
                drc0 = "/soc/drc@1e70000";
                drc0_in = "/soc/drc@1e70000/ports/port@0";
                drc0_in_be0 = "/soc/drc@1e70000/ports/port@0/endpoint";
                drc0_out = "/soc/drc@1e70000/ports/port@1";
                drc0_out_tcon0 = "/soc/drc@1e70000/ports/port@1/endpoint";
                rtc = "/soc/rtc@1f00000";
                r_intc = "/soc/interrupt-controller@1f00c00";
                ar100 = "/soc/prcm@1f01400/ar100-clk";
                ahb0 = "/soc/prcm@1f01400/ahb0-clk";
                apb0 = "/soc/prcm@1f01400/apb0-clk";
                apb0_gates = "/soc/prcm@1f01400/apb0-gates-clk";
                apb0_rst = "/soc/prcm@1f01400/apb0-rst";
                codec_analog = "/soc/prcm@1f01400/codec-analog";
                r_uart = "/soc/serial@1f02800";
                r_i2c = "/soc/i2c@1f02400";
                r_pio = "/soc/pinctrl@1f02c00";
                r_i2c_pins = "/soc/pinctrl@1f02c00/r-i2c-pins";
                r_rsb_pins = "/soc/pinctrl@1f02c00/r-rsb-pins";
                r_uart_pins_a = "/soc/pinctrl@1f02c00/r-uart-pins";
                r_rsb = "/soc/rsb@1f03400";
                axp22x = "/soc/rsb@1f03400/pmic@3a3";
                ac_power_supply = "/soc/rsb@1f03400/pmic@3a3/ac-power";
                axp_adc = "/soc/rsb@1f03400/pmic@3a3/adc";
                battery_power_supply = "/soc/rsb@1f03400/pmic@3a3/battery-power";
                axp_gpio = "/soc/rsb@1f03400/pmic@3a3/gpio";
                reg_dcdc1 = "/soc/rsb@1f03400/pmic@3a3/regulators/dcdc1";
                reg_dcdc2 = "/soc/rsb@1f03400/pmic@3a3/regulators/dcdc2";
                reg_dcdc3 = "/soc/rsb@1f03400/pmic@3a3/regulators/dcdc3";
                reg_dcdc4 = "/soc/rsb@1f03400/pmic@3a3/regulators/dcdc4";
                reg_dcdc5 = "/soc/rsb@1f03400/pmic@3a3/regulators/dcdc5";
                reg_dc1sw = "/soc/rsb@1f03400/pmic@3a3/regulators/dc1sw";
                reg_dc5ldo = "/soc/rsb@1f03400/pmic@3a3/regulators/dc5ldo";
                reg_aldo1 = "/soc/rsb@1f03400/pmic@3a3/regulators/aldo1";
                reg_aldo2 = "/soc/rsb@1f03400/pmic@3a3/regulators/aldo2";
                reg_aldo3 = "/soc/rsb@1f03400/pmic@3a3/regulators/aldo3";
                reg_dldo1 = "/soc/rsb@1f03400/pmic@3a3/regulators/dldo1";
                reg_dldo2 = "/soc/rsb@1f03400/pmic@3a3/regulators/dldo2";
                reg_dldo3 = "/soc/rsb@1f03400/pmic@3a3/regulators/dldo3";
                reg_dldo4 = "/soc/rsb@1f03400/pmic@3a3/regulators/dldo4";
                reg_eldo1 = "/soc/rsb@1f03400/pmic@3a3/regulators/eldo1";
                reg_eldo2 = "/soc/rsb@1f03400/pmic@3a3/regulators/eldo2";
                reg_eldo3 = "/soc/rsb@1f03400/pmic@3a3/regulators/eldo3";
                reg_ldo_io0 = "/soc/rsb@1f03400/pmic@3a3/regulators/ldo_io0";
                reg_ldo_io1 = "/soc/rsb@1f03400/pmic@3a3/regulators/ldo_io1";
                reg_rtc_ldo = "/soc/rsb@1f03400/pmic@3a3/regulators/rtc_ldo";
                reg_drivevbus = "/soc/rsb@1f03400/pmic@3a3/regulators/drivevbus";
                usb_power_supply = "/soc/rsb@1f03400/pmic@3a3/usb-power";
                crypto = "/soc/crypto-engine@1c15000";
                dai = "/soc/dai@1c22c00";
                codec = "/soc/codec@1c22e00";
                ths = "/soc/ths@1c25000";
                dsi = "/soc/dsi@1ca0000";
                dsi_in_tcon0 = "/soc/dsi@1ca0000/port/endpoint";
                dphy = "/soc/d-phy@1ca1000";
                cpu0_opp_table = "/opp-table-cpu";
                mali_opp_table = "/opp-table-gpu";
                sound = "/sound";
                link_codec = "/sound/simple-audio-card,codec";
                cpu_alert0 = "/thermal-zones/cpu-thermal/trips/cpu-alert0";
                gpu_alert0 = "/thermal-zones/cpu-thermal/trips/gpu-alert0";
                cpu_alert1 = "/thermal-zones/cpu-thermal/trips/cpu-alert1";
                gpu_alert1 = "/thermal-zones/cpu-thermal/trips/gpu-alert1";
                cpu_crit = "/thermal-zones/cpu-thermal/trips/cpu-crit";
                binman = "/binman";
        };
};
